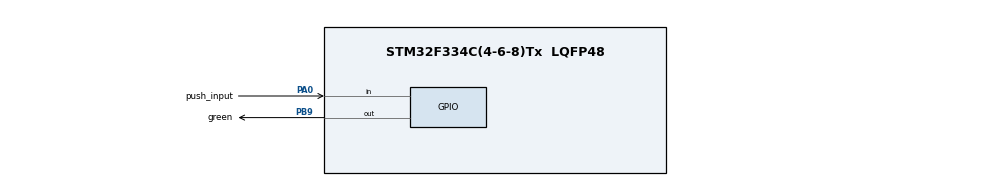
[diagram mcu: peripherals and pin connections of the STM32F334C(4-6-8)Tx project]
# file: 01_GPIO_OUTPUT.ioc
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Mcu.Family=STM32F3
Mcu.Name=STM32F334C(4-6-8)Tx
Mcu.Package=LQFP48
NVIC.PriorityGroup=NVIC_PRIORITYGROUP_0
PA0.GPIO_Label=push_input
PA0.Signal=GPIO_Input
PA13.GPIO_Label=SWDIO
PA13.Mode=Serial_Wire
PA13.Signal=SYS_JTMS-SWDIO
PA14.GPIO_Label=SWCLK
PA14.Mode=Serial_Wire
PA14.Signal=SYS_JTCK-SWCLK
PB9.GPIO_FM9=__NULL
PB9.GPIO_Label=green
PB9.GPIO_ModeDefaultOutputPP=GPIO_MODE_OUTPUT_PP
PB9.GPIO_PuPd=GPIO_NOPULL
PB9.GPIO_Speed=GPIO_SPEED_FREQ_LOW
PB9.Signal=GPIO_Output
ProjectManager.HeapSize=0x200
ProjectManager.StackSize=0x400
ProjectManager.TargetToolchain=STM32CubeIDE
RCC.AHBFreq_Value=36000000
RCC.APB1CLKDivider=RCC_HCLK_DIV2
RCC.APB1Freq_Value=18000000
RCC.APB1TimFreq_Value=36000000
RCC.APB2Freq_Value=36000000
RCC.APB2TimFreq_Value=36000000
RCC.CortexFreq_Value=36000000
RCC.HCLKFreq_Value=36000000
RCC.HSE_VALUE=8000000
RCC.HSI_VALUE=8000000
RCC.LSE_VALUE=32768
RCC.PLLMUL=RCC_PLL_MUL9
RCC.SYSCLKFreq_VALUE=36000000
RCC.SYSCLKSourceVirtual=RCC_SYSCLKSOURCE_PLLCLK
board=STM32F3348-DISCO

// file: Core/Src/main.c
/* USER CODE BEGIN Header */
/**
 ******************************************************************************
 * @file           : main.c
 * @brief          : Main program body
 ******************************************************************************
 * @attention
 *
 * Copyright (c) 2023 STMicroelectronics.
 * All rights reserved.
 *
 * This software is licensed under terms that can be found in the LICENSE file
 * in the root directory of this software component.
 * If no LICENSE file comes with this software, it is provided AS-IS.
 *
 ******************************************************************************
 */
/* USER CODE END Header */
#include "main.h"

void SystemClock_Config(void);
static void MX_GPIO_Init(void);

int main(void) {

	/* MCU Configuration--------------------------------------------------------*/

	/* Reset of all peripherals, Initializes the Flash interface and the Systick. */
	HAL_Init();

	/* Configure the system clock */
	SystemClock_Config();

	/* Initialize all configured peripherals */
	MX_GPIO_Init();

	/* Infinite loop */
	/* USER CODE BEGIN WHILE */
	while (1) {

		if(HAL_GPIO_ReadPin(push_input_GPIO_Port, push_input_Pin) == 1)
		HAL_GPIO_TogglePin(green_GPIO_Port, green_Pin);

	/* USER CODE END WHILE */

}
}

void SystemClock_Config(void) {
RCC_OscInitTypeDef RCC_OscInitStruct = { 0 };
RCC_ClkInitTypeDef RCC_ClkInitStruct = { 0 };

/** Initializes the RCC Oscillators according to the specified parameters
 * in the RCC_OscInitTypeDef structure.
 */
RCC_OscInitStruct.OscillatorType = RCC_OSCILLATORTYPE_HSI;
RCC_OscInitStruct.HSIState = RCC_HSI_ON;
RCC_OscInitStruct.HSICalibrationValue = RCC_HSICALIBRATION_DEFAULT;
RCC_OscInitStruct.PLL.PLLState = RCC_PLL_ON;
RCC_OscInitStruct.PLL.PLLSource = RCC_PLLSOURCE_HSI;
RCC_OscInitStruct.PLL.PLLMUL = RCC_PLL_MUL9;
if (HAL_RCC_OscConfig(&RCC_OscInitStruct) != HAL_OK) {
	Error_Handler();
}

/** Initializes the CPU, AHB and APB buses clocks
 */
RCC_ClkInitStruct.ClockType = RCC_CLOCKTYPE_HCLK | RCC_CLOCKTYPE_SYSCLK
		| RCC_CLOCKTYPE_PCLK1 | RCC_CLOCKTYPE_PCLK2;
RCC_ClkInitStruct.SYSCLKSource = RCC_SYSCLKSOURCE_PLLCLK;
RCC_ClkInitStruct.AHBCLKDivider = RCC_SYSCLK_DIV1;
RCC_ClkInitStruct.APB1CLKDivider = RCC_HCLK_DIV2;
RCC_ClkInitStruct.APB2CLKDivider = RCC_HCLK_DIV1;

if (HAL_RCC_ClockConfig(&RCC_ClkInitStruct, FLASH_LATENCY_1) != HAL_OK) {
	Error_Handler();
}
}

static void MX_GPIO_Init(void) {
GPIO_InitTypeDef GPIO_InitStruct = { 0 };

/* GPIO Ports Clock Enable */
__HAL_RCC_GPIOA_CLK_ENABLE();
__HAL_RCC_GPIOB_CLK_ENABLE();

/*Configure GPIO pin Output Level */
HAL_GPIO_WritePin(green_GPIO_Port, green_Pin, GPIO_PIN_RESET);

/*Configure GPIO pin : push_input_Pin */
GPIO_InitStruct.Pin = push_input_Pin;
GPIO_InitStruct.Mode = GPIO_MODE_INPUT;
GPIO_InitStruct.Pull = GPIO_NOPULL;
HAL_GPIO_Init(push_input_GPIO_Port, &GPIO_InitStruct);

/*Configure GPIO pin : green_Pin */
GPIO_InitStruct.Pin = green_Pin;
GPIO_InitStruct.Mode = GPIO_MODE_OUTPUT_PP;
GPIO_InitStruct.Pull = GPIO_NOPULL;
GPIO_InitStruct.Speed = GPIO_SPEED_FREQ_LOW;
HAL_GPIO_Init(green_GPIO_Port, &GPIO_InitStruct);

}

void Error_Handler(void) {
__disable_irq();
while (1) {
}
}
